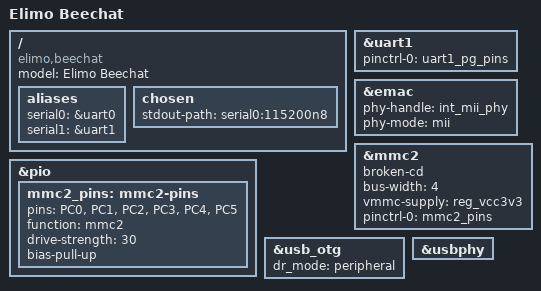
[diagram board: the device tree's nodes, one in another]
// SPDX-License-Identifier: (GPL-2.0+ OR MIT)
/*
 * Copyright (C) 2021 Matteo Scordino <matteo@elimo.io>
 */

/dts-v1/;
#include "sun8i-s3-elimo-impetus.dtsi"

/ {
	model = "Elimo Beechat";
	compatible = "elimo,beechat", "elimo,impetus", "sochip,s3",
    "allwinner,sun8i-v3";

	aliases {
		serial0 = &uart0;
		serial1 = &uart1;
	};

	chosen {
		stdout-path = "serial0:115200n8";
	};
};

&uart1 {
	pinctrl-0 = <&uart1_pg_pins>;
	pinctrl-names = "default";
	status = "okay";
};

&emac {
	phy-handle = <&int_mii_phy>;
	phy-mode = "mii";
	status = "okay";
};

&pio {
	mmc2_pins: mmc2-pins {
		pins = "PC0", "PC1", "PC2", "PC3",
		       "PC4", "PC5";
		function = "mmc2";
		drive-strength = <30>;
		bias-pull-up;
    };
};

&mmc2{
	broken-cd;
	bus-width = <4>;
	vmmc-supply = <&reg_vcc3v3>;
    pinctrl-names = "default";
	pinctrl-0 = <&mmc2_pins>;
    status = "okay";
};

&usb_otg {
    dr_mode = "peripheral";
    status = "okay";
};

&usbphy {
    status = "okay";
};
